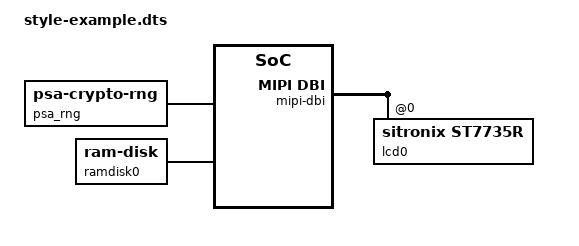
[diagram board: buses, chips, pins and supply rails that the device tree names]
/*
 * SPDX-FileCopyrightText: Copyright The Zephyr Project Contributors
 *
 * SPDX-License-Identifier: Apache-2.0
 *
 * Demonstration of permitted and disallowed coding style for devicetree files.
 */

/* start-after-here */

/dts-v1/;

/ {
	/* Node labels use the "_" separator, but node names use "-". */
	psa_rng: psa-rng {
		compatible = "zephyr,psa-crypto-rng";
		status = "okay";
	};

	ramdisk0 {
		compatible = "zephyr,ram-disk";
		/* Property names use the "-" separator. */
		disk-name = "RAM";
		sector-size = <512>;
		sector-count = <128>;
	};

	periph0 {
		/* Wrap array values to conform with line lengths. Indent
		 * continuation so that values align.
		 */
		pinctrl-0 = <&periph0_siga_px0_default &periph0_sigb_py7_default
			     &periph0_sigc_pz1_default>;
		pinctrl-names = "default";
	};

	mipi-dbi {
		compatible = "zephyr,mipi-dbi-spi";

		lcd0: lcd@0 {
			compatible = "sitronix,st7735r";
			/* Split array values across multiple lines to help readability. */
			gamctrp1 = [10 0e 02 03
				    0e 07 02 07
				    0a 12 27 37
				    00 0d 0e 10];
			gamctrn1 = [10 0e 03 03
				    0f 06 02 08
				    0a 13 26 36
				    00 0d 0e 10];
		};
	};
};
